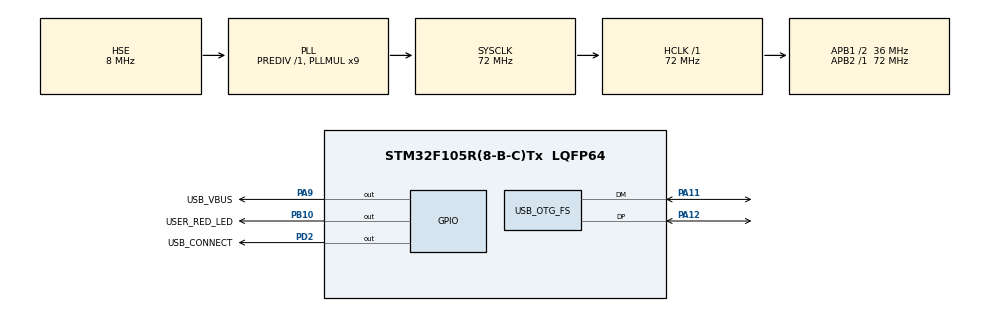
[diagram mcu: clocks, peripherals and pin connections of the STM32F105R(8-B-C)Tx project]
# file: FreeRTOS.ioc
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FREERTOS.Tasks01=defaultTask,24,128,StartDefaultTask,Default,NULL,Dynamic,NULL,NULL
FREERTOS.configUSE_TRACE_FACILITY=0
Mcu.Family=STM32F1
Mcu.Name=STM32F105R(8-B-C)Tx
Mcu.Package=LQFP64
NVIC.OTG_FS_IRQn=true\:5\:0\:false\:false\:true\:true\:false\:true\:true
NVIC.PriorityGroup=NVIC_PRIORITYGROUP_4
NVIC.TIM7_IRQn=true\:15\:0\:false\:false\:true\:false\:false\:true\:true
NVIC.TimeBase=TIM7_IRQn
NVIC.TimeBaseIP=TIM7
PA11.Mode=Device_Only
PA11.Signal=USB_OTG_FS_DM
PA12.Mode=Device_Only
PA12.Signal=USB_OTG_FS_DP
PA13.Mode=Trace_Asynchronous_SW
PA13.Signal=SYS_JTMS-SWDIO
PA14.Mode=Trace_Asynchronous_SW
PA14.Signal=SYS_JTCK-SWCLK
PA9.GPIO_Label=USB_VBUS
PA9.PinState=GPIO_PIN_SET
PA9.Signal=GPIO_Output
PB10.GPIO_Label=USER_RED_LED
PB10.PinState=GPIO_PIN_SET
PB10.Signal=GPIO_Output
PB3.Mode=Trace_Asynchronous_SW
PB3.Signal=SYS_TRACESWO
PC14-OSC32_IN.Mode=LSE-External-Oscillator
PC14-OSC32_IN.Signal=RCC_OSC32_IN
PC15-OSC32_OUT.Mode=LSE-External-Oscillator
PC15-OSC32_OUT.Signal=RCC_OSC32_OUT
PD0-OSC_IN.Mode=HSE-External-Oscillator
PD0-OSC_IN.Signal=RCC_OSC_IN
PD1-OSC_OUT.Mode=HSE-External-Oscillator
PD1-OSC_OUT.Signal=RCC_OSC_OUT
PD2.GPIO_Label=USB_CONNECT
PD2.PinState=GPIO_PIN_SET
PD2.Signal=GPIO_Output
ProjectManager.HeapSize=0x200
ProjectManager.StackSize=0x400
ProjectManager.TargetToolchain=STM32CubeIDE
RCC.AHBFreq_Value=72000000
RCC.APB1CLKDivider=RCC_HCLK_DIV2
RCC.APB1Freq_Value=36000000
RCC.APB1TimFreq_Value=72000000
RCC.APB2Freq_Value=72000000
RCC.APB2TimFreq_Value=72000000
RCC.HCLKFreq_Value=72000000
RCC.PLLMUL=RCC_PLL_MUL9
RCC.SYSCLKFreq_VALUE=72000000
RCC.SYSCLKSource=RCC_SYSCLKSOURCE_PLLCLK
RCC.USBFreq_Value=48000000
USB_DEVICE.CLASS_NAME_FS=HID
USB_DEVICE.USBD_DEBUG_LEVEL=3
USB_DEVICE.USBD_MAX_NUM_INTERFACES=0x1
USB_DEVICE.VirtualMode=Hid
USB_DEVICE.VirtualModeFS=Hid_FS
USB_OTG_FS.VirtualMode=Device_Only
VP_FREERTOS_VS_CMSIS_V2.Mode=CMSIS_V2
VP_SYS_VS_tim7.Mode=TIM7
VP_USB_DEVICE_VS_USB_DEVICE_HID_FS.Mode=HID_FS
board=custom

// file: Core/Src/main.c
/* USER CODE BEGIN Header */
/**
  ******************************************************************************
  * @file           : main.c
  * @brief          : Main program body
  ******************************************************************************
  * @attention
  *
  * Copyright (c) 2024 STMicroelectronics.
  * All rights reserved.
  *
  * This software is licensed under terms that can be found in the LICENSE file
  * in the root directory of this software component.
  * If no LICENSE file comes with this software, it is provided AS-IS.
  *
  ******************************************************************************
  */
/* USER CODE END Header */
#include "main.h"
#include "cmsis_os.h"
#include "usb_device.h"

/* Definitions for defaultTask */
osThreadId_t defaultTaskHandle;
const osThreadAttr_t defaultTask_attributes = {
        .name = "defaultTask",
        .stack_size = 128 * 4,
        .priority = (osPriority_t) osPriorityNormal,
};

void SystemClock_Config(void);

static void MX_GPIO_Init(void);

void StartDefaultTask(void *argument);

int main(void) {

    /* MCU Configuration--------------------------------------------------------*/

    /* Reset of all peripherals, Initializes the Flash interface and the Systick. */
    HAL_Init();

    /* Configure the system clock */
    SystemClock_Config();

    /* Initialize all configured peripherals */
    MX_GPIO_Init();

    /* Init scheduler */
    osKernelInitialize();

    /* Create the thread(s) */
    /* creation of defaultTask */
    defaultTaskHandle = osThreadNew(StartDefaultTask, NULL, &defaultTask_attributes);

    /* Start scheduler */
    osKernelStart();

    /* We should never get here as control is now taken by the scheduler */
    /* Infinite loop */
    while (1) {

    }
}

void SystemClock_Config(void) {
    RCC_OscInitTypeDef RCC_OscInitStruct = {0};
    RCC_ClkInitTypeDef RCC_ClkInitStruct = {0};
    RCC_PeriphCLKInitTypeDef PeriphClkInit = {0};

    /** Initializes the RCC Oscillators according to the specified parameters
    * in the RCC_OscInitTypeDef structure.
    */
    RCC_OscInitStruct.OscillatorType = RCC_OSCILLATORTYPE_HSE;
    RCC_OscInitStruct.HSEState = RCC_HSE_ON;
    RCC_OscInitStruct.HSEPredivValue = RCC_HSE_PREDIV_DIV1;
    RCC_OscInitStruct.HSIState = RCC_HSI_ON;
    RCC_OscInitStruct.Prediv1Source = RCC_PREDIV1_SOURCE_HSE;
    RCC_OscInitStruct.PLL.PLLState = RCC_PLL_ON;
    RCC_OscInitStruct.PLL.PLLSource = RCC_PLLSOURCE_HSE;
    RCC_OscInitStruct.PLL.PLLMUL = RCC_PLL_MUL9;
    RCC_OscInitStruct.PLL2.PLL2State = RCC_PLL_NONE;
    if (HAL_RCC_OscConfig(&RCC_OscInitStruct) != HAL_OK) {
        Error_Handler();
    }

    /** Initializes the CPU, AHB and APB buses clocks
    */
    RCC_ClkInitStruct.ClockType = RCC_CLOCKTYPE_HCLK | RCC_CLOCKTYPE_SYSCLK
                                  | RCC_CLOCKTYPE_PCLK1 | RCC_CLOCKTYPE_PCLK2;
    RCC_ClkInitStruct.SYSCLKSource = RCC_SYSCLKSOURCE_PLLCLK;
    RCC_ClkInitStruct.AHBCLKDivider = RCC_SYSCLK_DIV1;
    RCC_ClkInitStruct.APB1CLKDivider = RCC_HCLK_DIV2;
    RCC_ClkInitStruct.APB2CLKDivider = RCC_HCLK_DIV1;

    if (HAL_RCC_ClockConfig(&RCC_ClkInitStruct, FLASH_LATENCY_2) != HAL_OK) {
        Error_Handler();
    }
    PeriphClkInit.PeriphClockSelection = RCC_PERIPHCLK_USB;
    PeriphClkInit.UsbClockSelection = RCC_USBCLKSOURCE_PLL_DIV3;
    if (HAL_RCCEx_PeriphCLKConfig(&PeriphClkInit) != HAL_OK) {
        Error_Handler();
    }

    /** Configure the Systick interrupt time
    */
    __HAL_RCC_PLLI2S_ENABLE();
}

static void MX_GPIO_Init(void) {
    GPIO_InitTypeDef GPIO_InitStruct = {0};

    /* GPIO Ports Clock Enable */
    __HAL_RCC_GPIOC_CLK_ENABLE();
    __HAL_RCC_GPIOD_CLK_ENABLE();
    __HAL_RCC_GPIOB_CLK_ENABLE();
    __HAL_RCC_GPIOA_CLK_ENABLE();

    /*Configure GPIO pin Output Level */
    HAL_GPIO_WritePin(USER_RED_LED_GPIO_Port, USER_RED_LED_Pin, GPIO_PIN_SET);

    /*Configure GPIO pin Output Level */
    HAL_GPIO_WritePin(USB_VBUS_GPIO_Port, USB_VBUS_Pin, GPIO_PIN_SET);

    /*Configure GPIO pin Output Level */
    HAL_GPIO_WritePin(USB_CONNECT_GPIO_Port, USB_CONNECT_Pin, GPIO_PIN_SET);

    /*Configure GPIO pin : USER_RED_LED_Pin */
    GPIO_InitStruct.Pin = USER_RED_LED_Pin;
    GPIO_InitStruct.Mode = GPIO_MODE_OUTPUT_PP;
    GPIO_InitStruct.Pull = GPIO_NOPULL;
    GPIO_InitStruct.Speed = GPIO_SPEED_FREQ_LOW;
    HAL_GPIO_Init(USER_RED_LED_GPIO_Port, &GPIO_InitStruct);

    /*Configure GPIO pin : USB_VBUS_Pin */
    GPIO_InitStruct.Pin = USB_VBUS_Pin;
    GPIO_InitStruct.Mode = GPIO_MODE_OUTPUT_PP;
    GPIO_InitStruct.Pull = GPIO_NOPULL;
    GPIO_InitStruct.Speed = GPIO_SPEED_FREQ_LOW;
    HAL_GPIO_Init(USB_VBUS_GPIO_Port, &GPIO_InitStruct);

    /*Configure GPIO pin : USB_CONNECT_Pin */
    GPIO_InitStruct.Pin = USB_CONNECT_Pin;
    GPIO_InitStruct.Mode = GPIO_MODE_OUTPUT_PP;
    GPIO_InitStruct.Pull = GPIO_NOPULL;
    GPIO_InitStruct.Speed = GPIO_SPEED_FREQ_LOW;
    HAL_GPIO_Init(USB_CONNECT_GPIO_Port, &GPIO_InitStruct);

}

void StartDefaultTask(void *argument) {
    /* init code for USB_DEVICE */
    MX_USB_DEVICE_Init();
    HAL_GPIO_WritePin(USB_VBUS_GPIO_Port, USB_VBUS_Pin, GPIO_PIN_SET);
    HAL_GPIO_WritePin(USB_CONNECT_GPIO_Port, USB_CONNECT_Pin, GPIO_PIN_RESET);
    /* USER CODE BEGIN 5 */
    /* Infinite loop */
    for (;;) {
        HAL_GPIO_TogglePin(USER_RED_LED_GPIO_Port, USER_RED_LED_Pin);
        osDelay(50);
    }
    /* USER CODE END 5 */
}

void HAL_TIM_PeriodElapsedCallback(TIM_HandleTypeDef *htim) {
    if (htim->Instance == TIM7) {
        HAL_IncTick();
    }
}

void Error_Handler(void) {
    __disable_irq();
    while (1) {
    }
}
